# cslr_mcbspc55x_001 register map
Vendor: Texas Instruments
Peripheral module from a debugger description file.
Registers are 16-bit, read-write, reset 0x0 unless marked. A register's access mark holds for its fields unless they carry their own. Offsets are as the file gives them; lines under a group give offsets from that group; [hi:lo] are bit positions; {n}, {i} and the like mark numbered series; 'fields as' and 'values as' point back to an identical list; <NAME> marks a mode.

## McBSP — Multichannel Buffered Serial Port
0x00 DRR2 — Data Receive Registers
  [15:0] DRR2 — High part of receive data (for 20-, 24- or 32-bit data)
0x01 DRR1 — Data Receive Registers
  [15:0] DRR1 — Receive data (for 8-, 12-, or 16-bit data) or Low part of receive data (for 20-, 24- or 32-bit data)
0x02 DXR2 — Data Transmit Registers
  [15:0] DXR2 — High part of transmit data (for 20-, 24- or 32-bit data)
0x03 DXR1 — Data Transmit Registers
  [15:0] DXR1 — Transmit data (for 8-, 12-, or 16-bit data) or Low part of receive data (for 20-, 24- or 32-bit data)
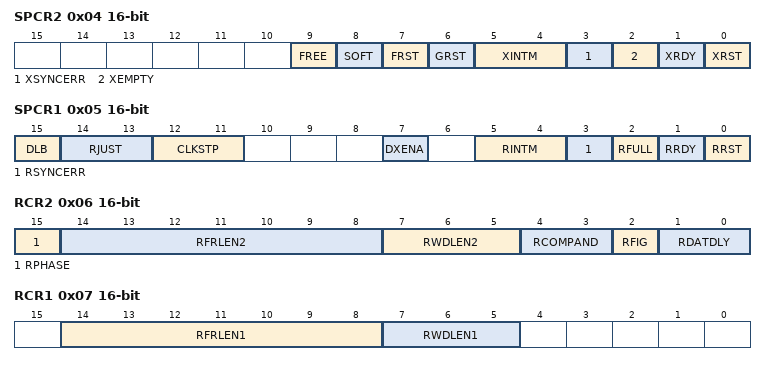
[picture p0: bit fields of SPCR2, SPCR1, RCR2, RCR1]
0x04 SPCR2 access per field — Serial Port Control Registers
  [9] FREE rw — Free run bit.
    0=The McBSP transmit and receive clocks are affected as determined by the SOFT bit; 1=Free run
  [8] SOFT rw — Soft stop bit.
    0=Hard stop; 1=Soft stop
  [7] FRST rw — Frame-sync logic reset bit.
    0=If you read a 0, the frame-sync logic is in its reset state. If you write a 0, you reset the frame-sync logic.; 1=If you read a 1, the frame-sync logic is enabled. If you write a 1, you enable the frame-sync logic by taking it out of its reset state.
  [6] GRST rw — Sample rate generator reset bit.
    0=If you read a 0, the sample rate generator is in its reset state. If you write a 0, you reset the sample rate generator.; 1=If you read a 1, the sample rate generator is enabled. If you write a 1, you enable the sample rate generator by taking it out of its reset state.
  [5:4] XINTM rw — Transmit interrupt mode bits.
    0=00b (The McBSP sends a transmit interrupt (XINT) request to the CPU when the XRDY bit changes from 0 to 1, indicating that transmitter is ready to accept new data (the content of DXR[1,2] has been copied to XSR[1,2])); 1=01b (In the multichannel selection mode, the McBSP sends an XINT request to the CPU after every 16-channel block is transmitted in a frame.); 2=10b (The McBSP sends an XINT request to the CPU when each transmit frame-sync pulse is detected.); 3=11b (The McBSP sends an XINT request to the CPU when the XSYNCERR bit is set, indicating a transmit frame-sync error.)
  [3] XSYNCERR rw — Transmit frame-sync error bit.
    0=No error; 1=Transmit frame-sync error
  [2] XEMPTY rw — Transmitter empty bit.
    0=Transmitter-empty condition; 1=No transmitter-empty condition
  [1] XRDY rw — Transmitter ready bit.
    0=Transmitter not ready; 1=Transmitter ready: DXR[1,2] is ready to accept new data
  [0] XRST rw — Transmitter reset bit.
    0=If you read a 0, the transmitter is in its reset state. If you write a 0, you reset the transmitter.; 1=If you read a 1, the transmitter is enabled. If you write a 1, you enable the transmitter by taking it out of its reset state.
0x05 SPCR1 access per field — Serial Port Control Registers
  [15] DLB rw — Digital loopback mode bit.
    0=Disabled; 1=Enabled
  [14:13] RJUST rw — Receive sign-extension and justification mode bits.
    0=00b (Right justify the data and zero fill the MSBs.); 1=01b (Right justify the data and sign-extend the data into the MSBs.); 2=10b (Left justify the data and zero fill the LSBs.); 3=11b (Reserved (do not use))
  [12:11] CLKSTP rw — Clock stop mode bits.
    1=10b (Clock stop mode, without clock delay); 2=11b (Clock stop mode, with half-cycle clock delay)
  [7] DXENA rw — DX delay enabler mode bit.
    0=DX delay enabler off; 1=DX delay enabler on
  [5:4] RINTM rw — Receive interrupt mode bits.
    0=00b (The McBSP sends a receive interrupt (RINT) request to the CPU when the RRDY bit changes from 0 to 1, indicating that receive data is ready to be read); 1=01b (In the multichannel selection mode, the McBSP sends a RINT request to the CPU after every 16-channel block is received in a frame.); 2=10b (The McBSP sends a RINT request to the CPU when each receive frame-sync pulse is detected.); 3=11b (The McBSP sends a RINT request to the CPU when the RSYNCERR bit is set, indicating a receive frame-sync error.)
  [3] RSYNCERR rw — Receive frame-sync error bit.
    0=No error; 1=Receive frame-sync error
  [2] RFULL ro — Receiver full bit.
    0=No receiver-full condition; 1=Receiver-full condition: RSR[1,2] and RBR[1,2] are full with new data, but the previous data in DRR[1,2] has not been read
  [1] RRDY ro — Receiver ready bit.
    0=Receiver not ready; 1=Receiver ready: New data can be read from DRR[1,2]
  [0] RRST rw — Receiver reset bit.
    0=If you read a 0, the receiver is in its reset state. If you write a 0, you reset the receiver.; 1=If you read a 1, the receiver is enabled. If you write a 1, you enable the receiver by taking it out of its reset state.
0x06 RCR2 — Receive Control Registers
  [15] RPHASE — Receive phase number bit.
    0=Single-phase frame; 1=Dual-phase frame
  [14:8] RFRLEN2 — Receive frame length 2 bits (1 to 128 words).
  [7:5] RWDLEN2 — Receive word length 2 bits.
    0=000b (8 bits); 1=001b (12 bits); 2=010b (16 bits); 3=011b (20 bits); 4=100b (24 bits); 5=101b (32 bits)
  [4:3] RCOMPAND — Receive companding mode bits.
    0=00b (No companding, any size data, MSB received first); 1=01b (No companding, 8-bit data, LSB received first); 2=10b (u-law companding, 8-bit data, MSB received first); 3=11b (A-law companding, 8-bit data, MSB received first)
  [2] RFIG — Receive frame-sync ignore bit.
    0=Frame-sync detect; 1=Frame-sync ignore
  [1:0] RDATDLY — Receive data delay bits.
    0=00b (0-bit data delay); 1=01b (1-bit data delay); 2=10b (2-bit data delay); 3=11b (Reserved (do not use))
0x07 RCR1 access per field — Receive Control Registers
  [14:8] RFRLEN1 rw — Receive frame length 1 bits (1 to 128 words).
  [7:5] RWDLEN1 rw — Receive word length 1 bits.
    values as RCR2.RWDLEN2
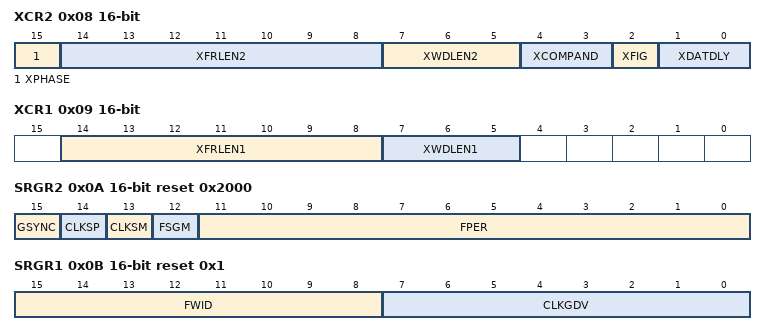
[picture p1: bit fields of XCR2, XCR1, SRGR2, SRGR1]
0x08 XCR2 — Transmit Control Registers
  [15] XPHASE — Transmit phase number bit.
    0=Single-phase frame; 1=Dual-phase frame
  [14:8] XFRLEN2 — Transmit frame length 2 (1 to 128 words).
  [7:5] XWDLEN2 — Transmit word length 2.
    values as RCR2.RWDLEN2
  [4:3] XCOMPAND — Transmit companding mode bits.
    0=00b (No companding, any size data, MSB transmitted first); 1=01b (No companding, 8-bit data, LSB transmitted first); 2=10b (u-law companding, 8-bit data, MSB transmitted first); 3=11b (A-law companding, 8-bit data, MSB transmitted first)
  [2] XFIG — Transmit frame-sync ignore bit.
    0=Frame-sync detect; 1=Frame-sync ignore
  [1:0] XDATDLY — Transmit data delay bits.
    values as RCR2.RDATDLY
0x09 XCR1 access per field — Transmit Control Registers
  [14:8] XFRLEN1 rw — Transmit frame length 1 (1 to 128 words).
  [7:5] XWDLEN1 rw — Transmit word length 1.
    values as RCR2.RWDLEN2
0x0A SRGR2 reset 0x2000 — Sample Rate Generator Registers
  [15] GSYNC — Frame-sync pulse width bits for FSG.
    0=No clock synchronization; 1=Clock synchronization
  [14] CLKSP — CLKS pin polarity bit.
    0=A rising edge on the CLKS pin; 1=A falling edge on the CLKS pin
  [13] CLKSM — Sample rate generator input clock mode bit.
    0=The input clock for the sample rate generator is taken from the CLKS pin or from the CLKR pin, depending on the value of the SCLKME bit of PCR; 1=The input clock for the sample rate generator is taken from the McBSP internal input clock or from the CLKX pin, depending on the value of the SCLKME bit of PCR
  [12] FSGM — Sample rate generator transmit frame-sync mode bit.
    0=If FSXM = 1, the McBSP generates a transmit frame-sync pulse when the content of DXR[1,2] is copied to XSR[1,2]; 1=If FSXM = 1, the transmitter uses frame-sync pulses generated by the sample rate generator
  [11:0] FPER — Frame-sync period bits for FSG.
0x0B SRGR1 reset 0x1 — Sample Rate Generator Registers
  [15:8] FWID — Frame-sync pulse width bits for FSG.
  [7:0] CLKGDV — Divide-down value for CLKG.
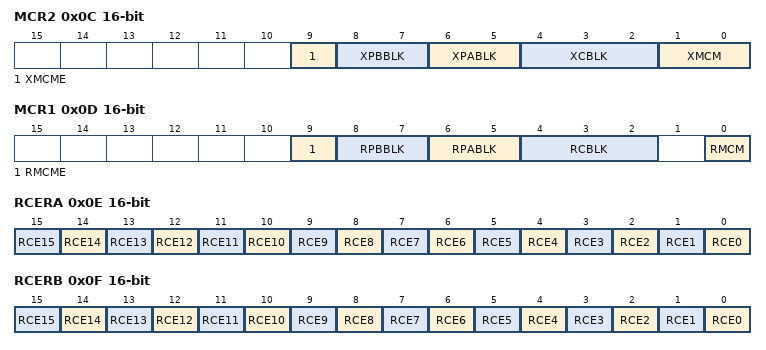
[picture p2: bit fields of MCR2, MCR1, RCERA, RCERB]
0x0C MCR2 access per field — Multichannel Control Registers
  [9] XMCME rw — Transmit multichannel partition mode bit.
    0=2-partition mode; 1=8-partition mode
  [8:7] XPBBLK rw — Transmit partition B block bits
    0=00b (Block 1: channels 16 through 31); 1=01b (Block 3: channels 48 through 63); 2=10b (Block 5: channels 80 through 95); 3=11b (Block 7: channels 112 through 127)
  [6:5] XPABLK rw — Transmit partition A block bits.
    0=00b (Block 0: channels 0 through 15); 1=01b (Block 2: channels 32 through 47); 2=10b (Block 4: channels 64 through 79); 3=11b (Block 6: channels 96 through 111)
  [4:2] XCBLK ro — Transmit current block indicator.
    0=000b (Block 0: channels 0 through 15); 1=001b (Block 1: channels 16 through 31); 2=010b (Block 2: channels 32 through 47); 3=011b (Block 3: channels 48 through 63); 4=100b (Block 4: channels 64 through 79); 5=101b (Block 5: channels 80 through 95); 6=110b (Block 6: channels 96 through 111); 7=111b (Block 7: channels 112 through 127)
  [1:0] XMCM rw — Transmit multichannel selection mode bits.
    0=00b (Transmit multichannel selection is off.); 1=01b (All channels are disabled unless they are selected in the appropriate transmit channel enable registers (XCERs).); 2=10b (All channels are enabled, but they are masked unless they are selected in the appropriate transmit channel enable registers (XCERs).); 3=11b (This mode is used for symmetric transmission and reception.)
0x0D MCR1 access per field — Multichannel Control Registers
  [9] RMCME rw — Receive multichannel partition mode bit.
    0=2-partition mode; 1=8-partition mode
  [8:7] RPBBLK rw — Receive partition B block bits
    values as MCR2.XPBBLK
  [6:5] RPABLK rw — Receive partition A block bits
    values as MCR2.XPABLK
  [4:2] RCBLK rw — Receive current block indicator.
    values as MCR2.XCBLK
  [0] RMCM rw — Receive multichannel selection mode bit.
    0=All 128 channels are enabled; 1=Multichannel selection mode
0x0E RCERA — Receive Channel Enable Registers
  [n] RCE{n} (n=0..15) — Receive channel enable bit
    0=Disable the channel that is mapped to RCE{n}; 1=Enable the channel that is mapped to RCE{n}
0x0F RCERB — Receive Channel Enable Registers
  fields as RCERA
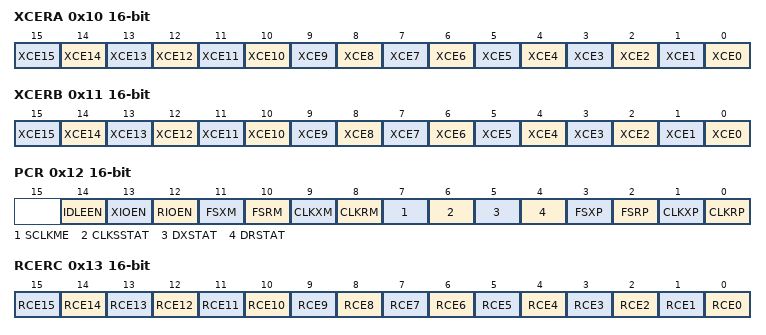
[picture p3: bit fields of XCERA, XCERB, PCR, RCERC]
0x10 XCERA — Transmit Channel Enable Registers
  [n] XCE{n} (n=0..15) — Transmit channel enable bit.
    0=Disable and mask the channel that is mapped to XCE{n}; 1=Enable and unmask the channel that is mapped to XCE{n}; 0=Mask the channel that is mapped to XCE{n}; 1=Unmask the channel that is mapped to XCE{n}; 0=Mask the channel that is mapped to XCE{n}; 1=Unmask the channel that is mapped to XCE{n}
0x11 XCERB — Transmit Channel Enable Registers
  fields as XCERA
0x12 PCR access per field — Pin Control Register
  [14] IDLEEN rw — This bit is the idle enable bit.
    0=The McBSP remains active when the PERIPH domain is idled; 1=If the PERIPH domain is idle (PERIS = 1 in the idle status register), the McBSP is stopped in a low-power state
  [13] XIOEN rw — Transmit I/O enable bit.
    0=The CLKX, FSX, DX, and CLKS pins are serial port pins; 1=If XRST = 0, the CLKX, FSX, and DX pins are GPIO pins
  [12] RIOEN rw — Receive I/O enable bit.
    0=The CLKR, FSR, DR, and CLKS pins are serial port pins; 1=If RRST = 0, the CLKR, FSR, and DR pins are GPIO pins
  [11] FSXM rw — Transmit frame-sync mode bit.
    0=Transmit frame synchronization is supplied by an external source via the FSX pin; 1=Transmit frame synchronization is supplied by the McBSP, as determined by the FSGM bit of SRGR2
  [10] FSRM rw — Receive frame-sync mode bit.
    0=Receive frame synchronization is supplied by an external source via the FSR pin; 1=Receive frame synchronization is supplied by the sample rate generator
  [9] CLKXM rw — Transmit clock mode bit.
    0=The transmitter gets its clock signal from an external source via the CLKX pin; 1=Internal CLKX is driven by the sample rate generator of the McBSP; 0=The McBSP is a slave in the SPI protocol; 1=The McBSP is a master in the SPI protocol
  [8] CLKRM rw — Receive clock mode bit.
    0=The CLKR pin is an input pin that supplies the internal receive clock (CLKR); 1=Internal CLKR is driven by the sample rate generator of the McBSP
  [7] SCLKME rw — Sample rate generator input clock mode bit.
    0=The input clock for the sample rate generator is taken from the CLKS pin or from the McBSP internal input clock, depending on the value of the CLKSM bit of SRGR2; 1=The input clock for the sample rate generator is taken from the CLKR pin or from the CLKX pin, depending on the value of the CLKSM bit of SRGR2
  [6] CLKSSTAT ro — CLKS pin status bit.
    0=The signal on the CLKS pin is low; 1=The signal on the CLKS pin is high
  [5] DXSTAT rw — DX pin status bit.
    0=Drive the signal on the DX pin low; 1=Drive the signal on the DX pin high
  [4] DRSTAT ro — DR pin status bit.
    0=The signal on DR pin is low; 1=The signal on DR pin is high
  [3] FSXP rw — Transmit frame-sync polarity bit.
    0=Transmit frame-sync pulses are active high; 1=Transmit frame-sync pulses are active low
  [2] FSRP rw — Receive frame-sync polarity bit.
    0=Receive frame-sync pulses are active high; 1=Receive frame-sync pulses are active low
  [1] CLKXP rw — Transmit clock polarity bit.
    0=Transmit data is driven on the rising edge of CLKX; 1=Transmit data is driven on the falling edge of CLKX
  [0] CLKRP rw — Receive clock polarity bit.
    0=When the CLKR pin is configured as an input, the external CLKR is not inverted before being used internally and the receive data is sampled on the falling edge of CLKR; 1=When the CLKR pin is configured as an input, the external CLKR is inverted before being used internally and the receive data is sampled on the rising edge of CLKR
0x13 RCERC — Receive Channel Enable Registers
  fields as RCERA
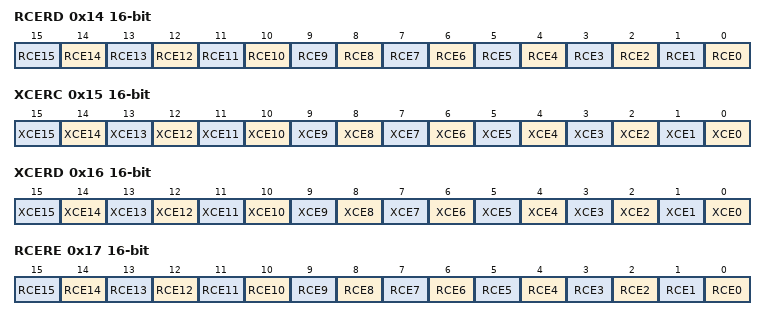
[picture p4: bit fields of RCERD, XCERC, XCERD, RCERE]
0x14 RCERD — Receive Channel Enable Registers
  fields as RCERA
0x15 XCERC — Transmit Channel Enable Registers
  fields as XCERA
0x16 XCERD — Transmit Channel Enable Registers
  fields as XCERA
0x17 RCERE — Receive Channel Enable Registers
  fields as RCERA
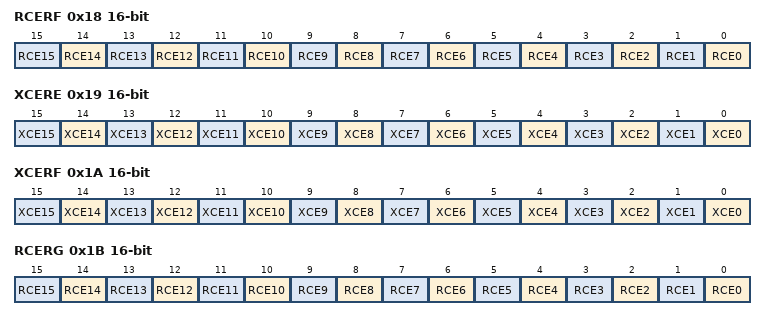
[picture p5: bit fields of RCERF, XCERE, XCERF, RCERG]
0x18 RCERF — Receive Channel Enable Registers
  fields as RCERA
0x19 XCERE — Transmit Channel Enable Registers
  fields as XCERA
0x1A XCERF — Transmit Channel Enable Registers
  fields as XCERA
0x1B RCERG — Receive Channel Enable Registers
  fields as RCERA
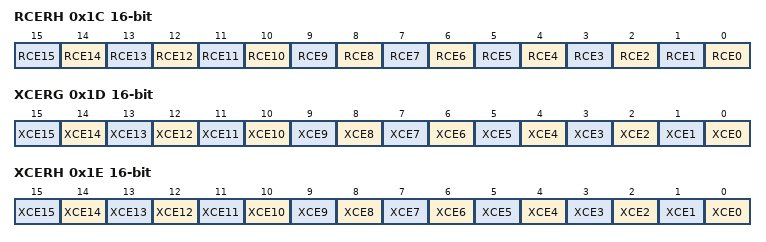
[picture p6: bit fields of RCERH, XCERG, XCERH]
0x1C RCERH — Receive Channel Enable Registers
  fields as RCERA
0x1D XCERG — Transmit Channel Enable Registers
  fields as XCERA
0x1E XCERH — Transmit Channel Enable Registers
  fields as XCERA
